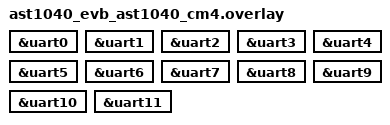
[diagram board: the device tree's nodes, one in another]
/*
 * Copyright (c) 2026 Aspeed Technology Inc.
 *
 * SPDX-License-Identifier: Apache-2.0
 *
 * uart12 is already enabled by the board dts as the console/shell UART.
 * This test only exercises internal (MCR loopback bit) loopback, which
 * never reaches the physical TX/RX pins, so no pinctrl-0 is needed here -
 * PINCTRL_DT_INST_DEFINE() tolerates its absence by generating an empty pin
 * state, and pinctrl_apply_state() with zero pins is a no-op at init.
 */
&uart0 {
	/delete-property/ pinctrl-names;
	/delete-property/ pinctrl-0;
	status = "okay";
};

&uart1 {
	/delete-property/ pinctrl-names;
	/delete-property/ pinctrl-0;
	status = "okay";
};

&uart2 {
	/delete-property/ pinctrl-names;
	/delete-property/ pinctrl-0;
	status = "okay";
};

&uart3 {
	/delete-property/ pinctrl-names;
	/delete-property/ pinctrl-0;
	status = "okay";
};

&uart4 {
	/delete-property/ pinctrl-names;
	/delete-property/ pinctrl-0;
	status = "okay";
};

&uart5 {
	/delete-property/ pinctrl-names;
	/delete-property/ pinctrl-0;
	status = "okay";
};

&uart6 {
	/delete-property/ pinctrl-names;
	/delete-property/ pinctrl-0;
	status = "okay";
};

&uart7 {
	/delete-property/ pinctrl-names;
	/delete-property/ pinctrl-0;
	status = "okay";
};

&uart8 {
	/delete-property/ pinctrl-names;
	/delete-property/ pinctrl-0;
	status = "okay";
};

&uart9 {
	/delete-property/ pinctrl-names;
	/delete-property/ pinctrl-0;
	status = "okay";
};

&uart10 {
	/delete-property/ pinctrl-names;
	/delete-property/ pinctrl-0;
	status = "okay";
};

&uart11 {
	/delete-property/ pinctrl-names;
	/delete-property/ pinctrl-0;
	status = "okay";
};
